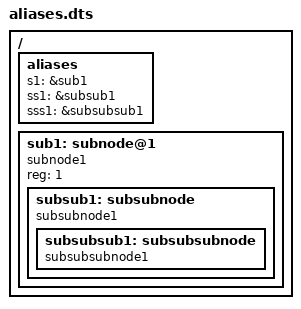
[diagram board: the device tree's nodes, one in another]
/dts-v1/;

/ {
	#address-cells = <1>;
	#size-cells = <0>;

	aliases {
		s1 = &sub1;
		ss1 = &subsub1;
		sss1 = &subsubsub1;
	};

	sub1: subnode@1 {
		compatible = "subnode1";
		reg = <1>;

		subsub1: subsubnode {
			compatible = "subsubnode1", "subsubnode";

			subsubsub1: subsubsubnode {
				compatible = "subsubsubnode1", "subsubsubnode";
			};
		};
	};
};
